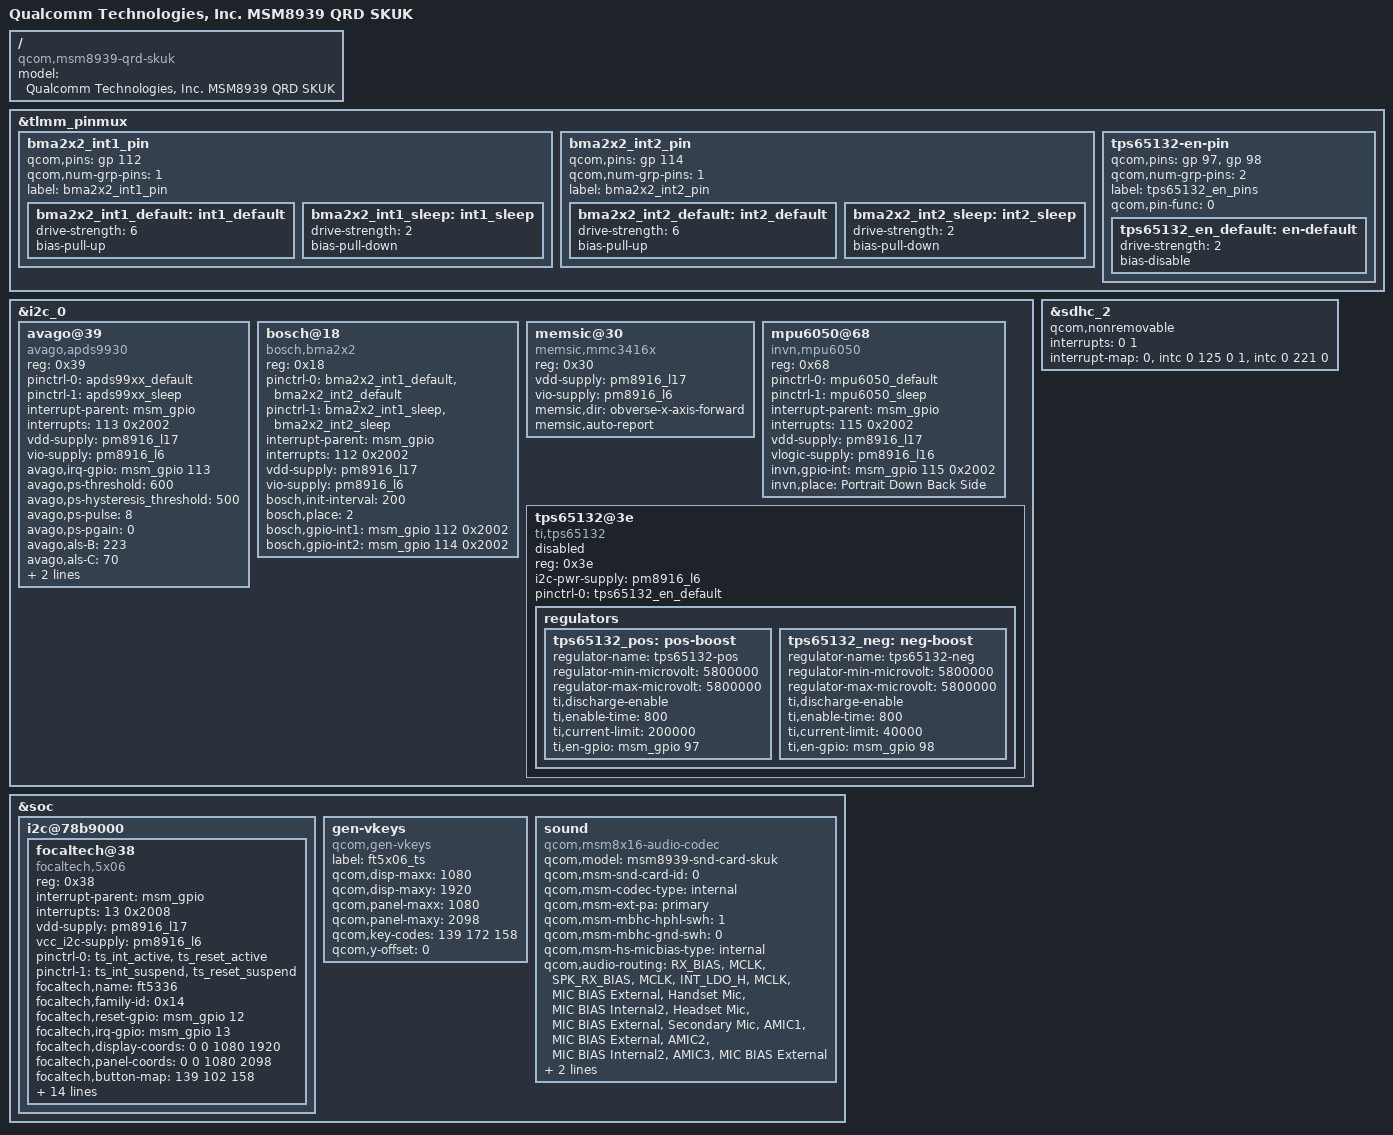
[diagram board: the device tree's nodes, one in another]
/* Copyright (c) 2014, The Linux Foundation. All rights reserved.
 *
 * This program is free software; you can redistribute it and/or modify
 * it under the terms of the GNU General Public License version 2 and
 * only version 2 as published by the Free Software Foundation.
 *
 * This program is distributed in the hope that it will be useful,
 * but WITHOUT ANY WARRANTY; without even the implied warranty of
 * MERCHANTABILITY or FITNESS FOR A PARTICULAR PURPOSE.  See the
 * GNU General Public License for more details.
 */

#include "msm8939-qrd.dtsi"

/ {
	model = "Qualcomm Technologies, Inc. MSM8939 QRD SKUK";
	compatible = "qcom,msm8939-qrd-skuk", "qcom,msm8939-qrd", "qcom,msm8939", "qcom,qrd";
};

&tlmm_pinmux {
	bma2x2_int1_pin {
		qcom,pins = <&gp 112>;
		qcom,num-grp-pins = <1>;
		label = "bma2x2_int1_pin";
		bma2x2_int1_default: int1_default {
			  drive-strength = <6>;
			  bias-pull-up;
		};
		bma2x2_int1_sleep: int1_sleep {
			  drive-strength = <2>;
			  bias-pull-down;
		};
	};

	bma2x2_int2_pin {
		qcom,pins = <&gp 114>;
		qcom,num-grp-pins = <1>;
		label = "bma2x2_int2_pin";
		bma2x2_int2_default: int2_default {
			  drive-strength = <6>;
			  bias-pull-up;
		};
		bma2x2_int2_sleep: int2_sleep {
			  drive-strength = <2>;
			  bias-pull-down;
		};
	};

	tps65132-en-pin {
		qcom,pins = <&gp 97>, <&gp 98>;
		qcom,num-grp-pins = <2>;
		label = "tps65132_en_pins";
		qcom,pin-func = <0>;

		tps65132_en_default: en-default {
			drive-strength = <2>;
			bias-disable;
		};
	};
};

&i2c_0 { /* BLSP1 QUP2 */
	avago@39 { /* Ambient light and proximity sensor */
		compatible = "avago,apds9930";
		reg = <0x39>;
		pinctrl-names = "apds_default","apds_sleep";
		pinctrl-0 = <&apds99xx_default>;
		pinctrl-1 = <&apds99xx_sleep>;
		interrupt-parent = <&msm_gpio>;
		interrupts = <113 0x2002>;
		vdd-supply = <&pm8916_l17>;
		vio-supply = <&pm8916_l6>;
		avago,irq-gpio = <&msm_gpio 113 0x2002>;
		avago,ps-threshold = <600>;
		avago,ps-hysteresis_threshold = <500>;
		avago,ps-pulse = <8>;
		avago,ps-pgain = <0>;
		avago,als-B = <223>;
		avago,als-C = <70>;
		avago,als-D = <142>;
		avago,ga-value = <48>;
	};

	bosch@18 { /* Accelerometer sensor */
		compatible = "bosch,bma2x2";
		reg = <0x18>;
		pinctrl-names = "bma_default","bma_sleep";
		pinctrl-0 = <&bma2x2_int1_default &bma2x2_int2_default>;
		pinctrl-1 = <&bma2x2_int1_sleep &bma2x2_int2_sleep>;
		interrupt-parent = <&msm_gpio>;
		interrupts = <112 0x2002>;
		vdd-supply = <&pm8916_l17>;
		vio-supply = <&pm8916_l6>;
		bosch,init-interval = <200>;
		bosch,place = <2>;
		bosch,gpio-int1 = <&msm_gpio 112 0x2002>;
		bosch,gpio-int2 = <&msm_gpio 114 0x2002>;
	};

	memsic@30 { /* Magnetic field sensor */
		compatible = "memsic,mmc3416x";
		reg = <0x30>;
		vdd-supply = <&pm8916_l17>;
		vio-supply = <&pm8916_l6>;
		memsic,dir = "obverse-x-axis-forward";
		memsic,auto-report;
	};

	mpu6050@68 { /* Gyroscope and accelerometer sensor combo */
		compatible = "invn,mpu6050";
		reg = <0x68>;
		pinctrl-names = "mpu_default","mpu_sleep";
		pinctrl-0 = <&mpu6050_default>;
		pinctrl-1 = <&mpu6050_sleep>;
		interrupt-parent = <&msm_gpio>;
		interrupts = <115 0x2002>;
		vdd-supply = <&pm8916_l17>;
		vlogic-supply = <&pm8916_l16>;
		invn,gpio-int = <&msm_gpio 115 0x2002>;
		invn,place = "Portrait Down Back Side";
	};

	tps65132@3e {
		compatible = "ti,tps65132";
		reg = <0x3e>;
		i2c-pwr-supply = <&pm8916_l6>;
		pinctrl-names = "default";
		pinctrl-0 = <&tps65132_en_default>;
		status = "disabled";

		regulators {
			tps65132_pos: pos-boost {
				regulator-name = "tps65132-pos";
				regulator-min-microvolt = <5800000>;
				regulator-max-microvolt = <5800000>;
				ti,discharge-enable;
				ti,enable-time = <800>;
				ti,current-limit = <200000>;
				ti,en-gpio = <&msm_gpio 97 0>;
			};

			tps65132_neg: neg-boost {
				regulator-name = "tps65132-neg";
				regulator-min-microvolt = <5800000>;
				regulator-max-microvolt = <5800000>;
				ti,discharge-enable;
				ti,enable-time = <800>;
				ti,current-limit = <40000>;
				ti,en-gpio = <&msm_gpio 98 0>;
			};
		};
	};
};

&soc {
	i2c@78b9000 { /* BLSP1 QUP5 */
		focaltech@38 {
			compatible = "focaltech,5x06";
			reg = <0x38>;
			interrupt-parent = <&msm_gpio>;
			interrupts = <13 0x2008>;
			vdd-supply = <&pm8916_l17>;
			vcc_i2c-supply = <&pm8916_l6>;
			/* pins used by touchscreen */
			pinctrl-names = "pmx_ts_active","pmx_ts_suspend";
			pinctrl-0 = <&ts_int_active &ts_reset_active>;
			pinctrl-1 = <&ts_int_suspend &ts_reset_suspend>;
			focaltech,name = "ft5336";
			focaltech,family-id = <0x14>;
			focaltech,reset-gpio = <&msm_gpio 12 0x0>;
			focaltech,irq-gpio = <&msm_gpio 13 0x2008>;
			focaltech,display-coords = <0 0 1080 1920>;
			focaltech,panel-coords = <0 0 1080 2098>;
			focaltech,button-map= <139 102 158>;
			focaltech,no-force-update;
			focaltech,i2c-pull-up;
			focaltech,group-id = <1>;
			focaltech,hard-reset-delay-ms = <20>;
			focaltech,soft-reset-delay-ms = <200>;
			focaltech,num-max-touches = <5>;
			focaltech,fw-delay-aa-ms = <30>;
			focaltech,fw-delay-55-ms = <30>;
			focaltech,fw-upgrade-id1 = <0x11>;
			focaltech,fw-upgrade-id2 = <0x11>;
			focaltech,fw-delay-readid-ms = <10>;
			focaltech,fw-delay-era-flsh-ms = <2000>;
			focaltech,fw-auto-cal;
			focaltech,ignore-id-check;
		};
	};

	gen-vkeys {
		compatible = "qcom,gen-vkeys";
		label = "ft5x06_ts";
		qcom,disp-maxx = <1080>;
		qcom,disp-maxy = <1920>;
		qcom,panel-maxx = <1080>;
		qcom,panel-maxy = <2098>;
		qcom,key-codes = <139 172 158>;
		qcom,y-offset = <0>;
	};

	sound {
		compatible = "qcom,msm8x16-audio-codec";
		qcom,model = "msm8939-snd-card-skuk";
		qcom,msm-snd-card-id = <0>;
		qcom,msm-codec-type = "internal";
		qcom,msm-ext-pa = "primary";
		qcom,msm-mbhc-hphl-swh = <1>;
		qcom,msm-mbhc-gnd-swh = <0>;
		qcom,msm-hs-micbias-type = "internal";
		qcom,audio-routing =
			"RX_BIAS", "MCLK",
			"SPK_RX_BIAS", "MCLK",
			"INT_LDO_H", "MCLK",
			"MIC BIAS External", "Handset Mic",
			"MIC BIAS Internal2", "Headset Mic",
			"MIC BIAS External", "Secondary Mic",
			"AMIC1", "MIC BIAS External",
			"AMIC2", "MIC BIAS Internal2",
			"AMIC3", "MIC BIAS External";
		pinctrl-names = "cdc_lines_act",
				"cdc_lines_sus";
		pinctrl-0 = <&cdc_pdm_lines_act>;
		pinctrl-1 = <&cdc_pdm_lines_sus>;
	};
};

&sdhc_2 {
	qcom,nonremovable;

	interrupts = <0 1>;
	interrupt-map = <0 &intc 0 125 0
		1 &intc 0 221 0>;
	interrupt-names = "hc_irq", "pwr_irq";
	/delete-property/ cd-gpios;
};

